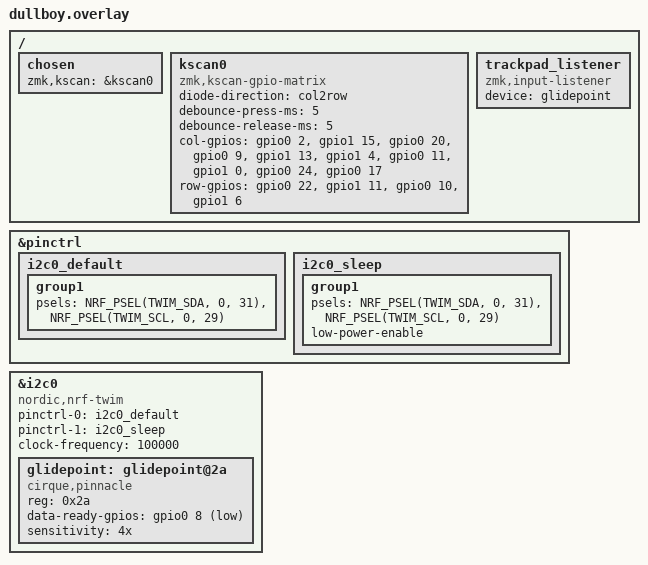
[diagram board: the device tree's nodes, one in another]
#include <dt-bindings/pinctrl/nrf-pinctrl.h>

/ {
    chosen {
        zmk,kscan = &kscan0;
    };

    kscan0: kscan0 {
        compatible = "zmk,kscan-gpio-matrix";
        diode-direction = "col2row";
        debounce-press-ms = <5>;
        debounce-release-ms = <5>;

        col-gpios =
            <&gpio0  2 GPIO_ACTIVE_HIGH>,
            <&gpio1 15 GPIO_ACTIVE_HIGH>,
            <&gpio0 20 GPIO_ACTIVE_HIGH>,
            <&gpio0  9 GPIO_ACTIVE_HIGH>,
            <&gpio1 13 GPIO_ACTIVE_HIGH>,
            <&gpio1  4 GPIO_ACTIVE_HIGH>,
            <&gpio0 11 GPIO_ACTIVE_HIGH>,
            <&gpio1  0 GPIO_ACTIVE_HIGH>,
            <&gpio0 24 GPIO_ACTIVE_HIGH>,
            <&gpio0 17 GPIO_ACTIVE_HIGH>;

        row-gpios =
            <&gpio0 22 (GPIO_ACTIVE_HIGH | GPIO_PULL_DOWN)>,
            <&gpio1 11 (GPIO_ACTIVE_HIGH | GPIO_PULL_DOWN)>,
            <&gpio0 10 (GPIO_ACTIVE_HIGH | GPIO_PULL_DOWN)>,
            <&gpio1  6 (GPIO_ACTIVE_HIGH | GPIO_PULL_DOWN)>;
    };
};

&pinctrl {
    i2c0_default: i2c0_default {
        group1 {
            psels =
                <NRF_PSEL(TWIM_SDA, 0, 31)>,
                <NRF_PSEL(TWIM_SCL, 0, 29)>;
        };
    };

    i2c0_sleep: i2c0_sleep {
        group1 {
            psels =
                <NRF_PSEL(TWIM_SDA, 0, 31)>,
                <NRF_PSEL(TWIM_SCL, 0, 29)>;
            low-power-enable;
        };
    };
};

&i2c0 {
    compatible = "nordic,nrf-twim";
    status = "okay";

    pinctrl-0 = <&i2c0_default>;
    pinctrl-1 = <&i2c0_sleep>;
    pinctrl-names = "default", "sleep";

    clock-frequency = <100000>;

    glidepoint: glidepoint@2a {
        compatible = "cirque,pinnacle";
        reg = <0x2a>;
        status = "okay";

        /* DR / Data Ready : OBLIGATOIRE pour le mode relatif.
           Remplace <&gpio0 6> par la GPIO réellement soudée au pad DR (J1 pin 4). */
        data-ready-gpios = <&gpio0 8 GPIO_ACTIVE_LOW>;
        sensitivity = "4x";
    };
};

/ {
    trackpad_listener {
        compatible = "zmk,input-listener";
        device = <&glidepoint>;
    };
};
